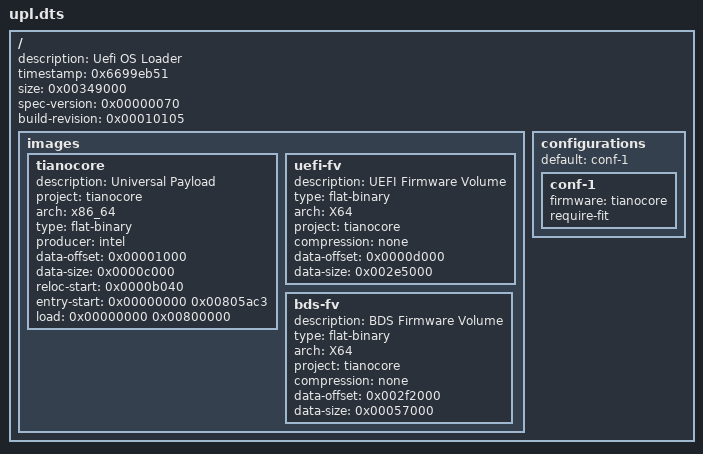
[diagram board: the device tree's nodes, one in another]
/dts-v1/;
// magic:		0xd00dfeed
// totalsize:		0x1000 (4096)
// off_dt_struct:	0x40
// off_dt_strings:	0x350
// off_mem_rsvmap:	0x30
// version:		17
// last_comp_version:	16
// boot_cpuid_phys:	0x0
// size_dt_strings:	0xbe
// size_dt_struct:	0x310

/ {
    description = "Uefi OS Loader";
    timestamp = <0x6699eb51>;
    size = <0x00349000>;
    spec-version = <0x00000070>;
    build-revision  = <0x00010105>;
    images {
        tianocore {
            description = "Universal Payload";
            project  = "tianocore";
            arch  = "x86_64";
            type  = "flat-binary";
            producer  = "intel";
            data-offset = <0x00001000>;
            data-size = <0x0000c000>;
            reloc-start = <0x0000b040>;
            entry-start = <0x00000000 0x00805ac3>;
            load = <0x00000000 0x00800000>;
        };
        uefi-fv {
            description = "UEFI Firmware Volume";
            type = "flat-binary";
            arch = "X64";
            project  = "tianocore";
            compression = "none";
            data-offset = <0x0000d000>;
            data-size = <0x002e5000>;
        };
        bds-fv {
            description = "BDS Firmware Volume";
            type = "flat-binary";
            arch = "X64";
            project  = "tianocore";
            compression = "none";
            data-offset = <0x002f2000>;
            data-size = <0x00057000>;
        };
    };
    configurations {
        default  = "conf-1";
        conf-1 {
            firmware = "tianocore";
            require-fit;
        };
    };
};
